# RZT2ME register map
Vendor: Renesas Electronics Corporation; Series: RZT; File version: 1.00.00
CPU: other r0p0, little endian, MPU, no FPU, VTOR, 4 interrupt priority bits, 624 interrupts
Registers are 32-bit, read-write, reset 0x0 unless marked. A register's access mark holds for its fields unless they carry their own. Offsets are from the block's base; [hi:lo] are bit positions.

## MTU4 — Multi-Function Timer Pulse Unit Channel 4
Base 0x90001200
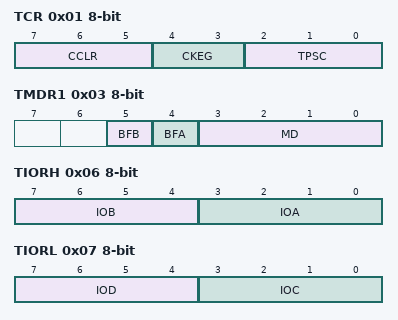
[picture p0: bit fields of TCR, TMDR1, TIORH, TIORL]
0x01 TCR 8-bit — Timer Control Register
  [7:5] CCLR — Counter Clear Source Select
  [4:3] CKEG — Clock Edge Select
    0=Count at rising edge; 1=Count at falling edge; 0b1x=Count at both edges
  [2:0] TPSC — Time Prescaler Select
0x03 TMDR1 8-bit — Timer Mode Register 1
  [5] BFB — Buffer Operation B
    0=TGRB and TGRD operate normally; 1=TGRB and TGRD used together for buffer operation
  [4] BFA — Buffer Operation A
    0=TGRA and TGRC operate normally; 1=TGRA and TGRC used together for buffer operation
  [3:0] MD — Mode Select
0x06 TIORH 8-bit — Timer I/O Control Register H
  [7:4] IOB — I/O Control B
  [3:0] IOA — I/O Control A
0x07 TIORL 8-bit — Timer I/O Control Register L
  [7:4] IOD — I/O Control B
  [3:0] IOC — I/O Control A
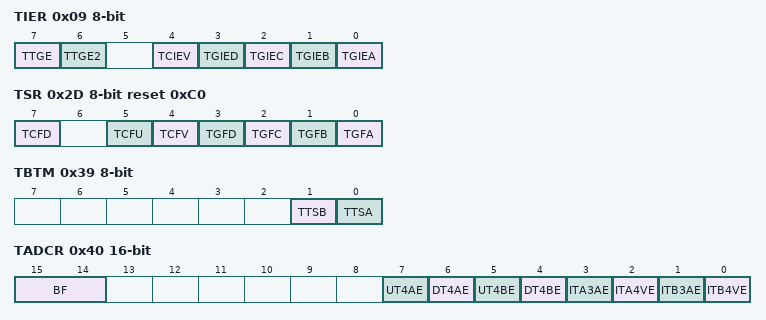
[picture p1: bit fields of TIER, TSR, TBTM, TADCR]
0x09 TIER 8-bit — Timer Interrupt Enable Register
  [7] TTGE — A/D Converter Start Request Enable
    0=A/D converter start request generation disabled; 1=A/D converter start request generation enabled
  [6] TTGE2 — A/D Converter Start Request Enable 2
    0=A/D converter start request generation by MTUn.TCNT underflow (trough) disabled; 1=A/D converter start request generation by MTUn.TCNT underflow (trough) enabled
  [4] TCIEV — Overflow Interrupt Enable
    0=Interrupt requests (TCIV) disabled; 1=Interrupt requests (TCIV) enabled
  [3] TGIED — TGR Interrupt Enable D
    0=Interrupt requests (TGID) disabled; 1=Interrupt requests (TGID) enabled
  [2] TGIEC — TGR Interrupt Enable C
    0=Interrupt requests (TGIC) disabled; 1=Interrupt requests (TGIC) enabled
  [1] TGIEB — TGR Interrupt Enable B
    0=Interrupt requests (TGIB) disabled; 1=Interrupt requests (TGIB) enabled
  [0] TGIEA — TGR Interrupt Enable A
    0=Interrupt requests (TGIA) disabled; 1=Interrupt requests (TGIA) enabled
0x12 TCNT 16-bit — Timer Counter
0x1C TGRA 16-bit reset 0xFFFF — Timer General Register A
0x1E TGRB 16-bit reset 0xFFFF — Timer General Register B
0x28 TGRC 16-bit reset 0xFFFF — Timer General Register C
0x2A TGRD 16-bit reset 0xFFFF — Timer General Register D
0x2D TSR 8-bit reset 0xC0 — Timer Status Register
  [7] TCFD ro — Count Direction Flag
    0=TCNT counts down; 1=TCNT counts up
  [5] TCFU — Underflow flag
    0=TCNT underflow has not occurred when MTU1 and MTU2 are in phase counting mode; 1=TCNT underflow has occurred when MTU1 and MTU2 are in phase counting mode
  [4] TCFV — Overflow flag
    0=TCNT overflow has not occurred; 1=TCNT overflow has occurred
  [3] TGFD — Input Capture/Output Compare Flag D
    0=TGRD input capture or compare match has not occurred; 1=TGRD input capture or compare match has occurred
  [2] TGFC — Input Capture/Output Compare Flag C
    0=TGRC input capture or compare match has not occurred; 1=TGRC input capture or compare match has occurred
  [1] TGFB — Input Capture/Output Compare Flag B
    0=TGRB input capture or compare match has not occurred; 1=TGRB input capture or compare match has occurred
  [0] TGFA — Input Capture/Output Compare Flag A
    0=TGRA input capture or compare match has not occurred; 1=TGRA input capture or compare match has occurred
0x39 TBTM 8-bit — Timer Buffer Operation Transfer Mode Register
  [1] TTSB — Timing Select B
    0=When compare match B occurs in each channel, data is transferred from TGRD to TGRB; 1=When TCNT is cleared in each channel, data is transferred from TGRD to TGRB
  [0] TTSA — Timing Select A
    0=When compare match A occurs in each channel, data is transferred from TGRC to TGRA; 1=When TCNT is cleared in each channel, data is transferred from TGRC to TGRA
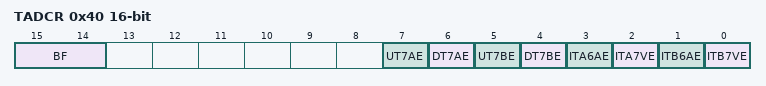
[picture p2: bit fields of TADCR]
0x40 TADCR 16-bit — Timer A/D Converter Start Request Control Register
  [15:14] BF — MTU4.TADCOBRA/TADCOBRB Transfer Timing Select
  [7] UT4AE — Up-Count TRG4AN Enable
    0=A/D converter start requests (TRG4AN) disabled during MTU4.TCNT up-count operation; 1=A/D converter start requests (TRG4AN) enabled during MTU4.TCNT up-count operation
  [6] DT4AE — Down-Count TRG4AN Enable
    0=A/D converter start requests (TRG4AN) disabled during MTU4.TCNT down-count operation; 1=A/D converter start requests (TRG4AN) enabled during MTU4.TCNT down-count operation
  [5] UT4BE — Up-Count TRG4BN Enable
    0=A/D converter start requests (TRG4BN) disabled during MTU4.TCNT up-count operation; 1=A/D converter start requests (TRG4BN) enabled during MTU4.TCNT up-count operation
  [4] DT4BE — Down-Count TRG4BN Enable
    0=A/D converter start requests (TRG4BN) disabled during MTU4.TCNT down-count operation; 1=A/D converter start requests (TRG4BN) enabled during MTU4.TCNT down-count operation
  [3] ITA3AE — TGIA3 Interrupt Skipping Link Enable
    0=A/D converter start request signal TRG4AN and TGIA3 interrupt skipping 1 are not linked; 1=A/D converter start request signal TRG4AN and TGIA3 interrupt skipping 1 are linked
  [2] ITA4VE — TCIV4 Interrupt Skipping Link Enable
    0=A/D converter start request signal TRG4AN and TCIV4 interrupt skipping 1 are not linked; 1=A/D converter start request signal TRG4AN and TCIV4 interrupt skipping 1 are linked
  [1] ITB3AE — TGIA3 Interrupt Skipping Link Enable
    0=A/D converter start request signal TRG4BN and TGIA3 interrupt skipping 1 are not linked; 1=A/D converter start request signal TRG4BN and TGIA3 interrupt skipping 1 are linked
  [0] ITB4VE — TCIV4 Interrupt Skipping Link Enable
    0=A/D converter start request signal TRG4BN and TCIV4 interrupt skipping 1 are not linked; 1=A/D converter start request signal TRG4BN and TCIV4 interrupt skipping 1 are linked
0x44 TADCORA 16-bit reset 0xFFFF — Timer A/D Converter Start Request Cycle Set Register A
0x46 TADCORB 16-bit reset 0xFFFF — Timer A/D Converter Start Request Cycle Set Register B
0x48 TADCOBRA 16-bit reset 0xFFFF — Timer A/D Converter Start Request Cycle Set Buffer Register A
0x4A TADCOBRB 16-bit reset 0xFFFF — Timer A/D Converter Start Request Cycle Set Buffer Register B
0x4D TCR2 8-bit — Timer Control Register 2
  [2:0] TPSC2 — Time Prescaler Select
0x74 TGRE 16-bit reset 0xFFFF — Timer General Register E
0x76 TGRF 16-bit reset 0xFFFF — Timer General Register F

## MTU7 — Multi-Function Timer Pulse Unit Channel 7
Base 0x90001A00
Registers as MTU4; these are added or differ:
0x40 TADCR 16-bit — Timer A/D Converter Start Request Control Register
  [15:14] BF — MTU7.TADCOBRA/TADCOBRB Transfer Timing Select
  [7] UT7AE — Up-Count TRG7AN Enable
    0=A/D converter start requests (TRG7AN) disabled during MTU7.TCNT up-count operation; 1=A/D converter start requests (TRG7AN) enabled during MTU7.TCNT up-count operation
  [6] DT7AE — Down-Count TRG7AN Enable
    0=A/D converter start requests (TRG7AN) disabled during MTU7.TCNT down-count operation; 1=A/D converter start requests (TRG7AN) enabled during MTU7.TCNT down-count operation
  [5] UT7BE — Up-Count TRG7BN Enable
    0=A/D converter start requests (TRG7BN) disabled during MTU7.TCNT up-count operation; 1=A/D converter start requests (TRG7BN) enabled during MTU7.TCNT up-count operation
  [4] DT7BE — Down-Count TRG7BN Enable
    0=A/D converter start requests (TRG7BN) disabled during MTU7.TCNT down-count operation; 1=A/D converter start requests (TRG7BN) enabled during MTU7.TCNT down-count operation
  [3] ITA6AE — TGIA6 Interrupt Skipping Link Enable
    0=A/D converter start request signal TRG7AN and TGIA6 interrupt skipping 1 are not linked; 1=A/D converter start request signal TRG7AN and TGIA6 interrupt skipping 1 are linked
  [2] ITA7VE — TCIV7 Interrupt Skipping Link Enable
    0=A/D converter start request signal TRG7AN and TCIV7 interrupt skipping 1 are not linked; 1=A/D converter start request signal TRG7AN and TCIV7 interrupt skipping 1 are linked
  [1] ITB6AE — TGIA6 Interrupt Skipping Link Enable
    0=A/D converter start request signal TRG7BN and TGIA6 interrupt skipping 1 are not linked; 1=A/D converter start request signal TRG7BN and TGIA6 interrupt skipping 1 are linked
  [0] ITB7VE — TCIV7 Interrupt Skipping Link Enable
    0=A/D converter start request signal TRG7BN and TCIV7 interrupt skipping 1 are not linked; 1=A/D converter start request signal TRG7BN and TCIV7 interrupt skipping 1 are linked
